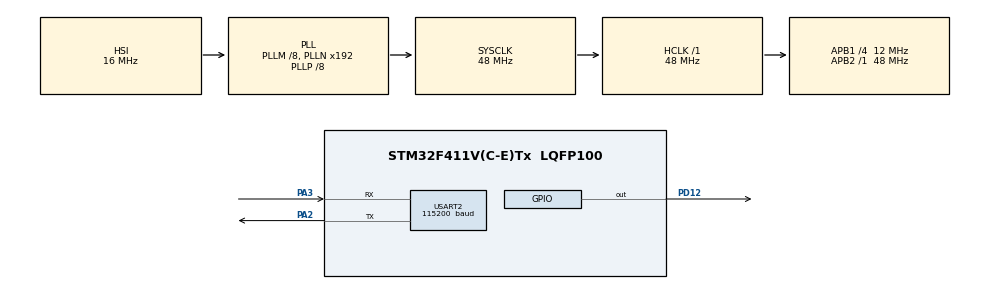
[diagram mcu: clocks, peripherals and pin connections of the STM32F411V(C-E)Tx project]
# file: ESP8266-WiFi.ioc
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Mcu.Family=STM32F4
Mcu.Name=STM32F411V(C-E)Tx
Mcu.Package=LQFP100
NVIC.PriorityGroup=NVIC_PRIORITYGROUP_0
NVIC.USART2_IRQn=true\:0\:0\:false\:false\:true\:true\:true\:true
PA2.Mode=Asynchronous
PA2.Signal=USART2_TX
PA3.Mode=Asynchronous
PA3.Signal=USART2_RX
PD12.Signal=GPIO_Output
ProjectManager.HeapSize=0x200
ProjectManager.StackSize=0x400
ProjectManager.TargetToolchain=STM32CubeIDE
RCC.48MHZClocksFreq_Value=48000000
RCC.AHBFreq_Value=48000000
RCC.APB1CLKDivider=RCC_HCLK_DIV4
RCC.APB1Freq_Value=12000000
RCC.APB1TimFreq_Value=24000000
RCC.APB2Freq_Value=48000000
RCC.APB2TimFreq_Value=48000000
RCC.CortexFreq_Value=48000000
RCC.HCLKFreq_Value=48000000
RCC.HSE_VALUE=8000000
RCC.HSI_VALUE=16000000
RCC.LSE_VALUE=32768
RCC.PLLI2SM=5
RCC.PLLI2SN=200
RCC.PLLM=8
RCC.PLLP=RCC_PLLP_DIV8
RCC.PLLQ=8
RCC.SYSCLKFreq_VALUE=48000000
RCC.SYSCLKSource=RCC_SYSCLKSOURCE_PLLCLK
RCC.VCOOutputFreq_Value=384000000
USART2.BaudRate=115200 
USART2.VirtualMode=VM_ASYNC
board=STM32F411E-DISCO

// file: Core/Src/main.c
/* USER CODE BEGIN Header */
/**
  ******************************************************************************
  * @file           : main.c
  * @brief          : Main program body
  ******************************************************************************
  * @attention
  *
  * Copyright (c) 2025 STMicroelectronics.
  * All rights reserved.
  *
  * This software is licensed under terms that can be found in the LICENSE file
  * in the root directory of this software component.
  * If no LICENSE file comes with this software, it is provided AS-IS.
  *
  ******************************************************************************
  */
/* USER CODE END Header */
#include "main.h"

/* USER CODE BEGIN Includes */
#include <string.h>
#include <stdio.h>
#include <stdlib.h>
#include <stdbool.h>  // Necesario para usar bool en C

/* USER CODE END Includes */

/* USER CODE BEGIN PD */
#define WIFI_SSID "MOVISTAR_1DD2"
#define WIFI_PASS "55253A2D16DDBF32D47B"
#define THINGSPEAK_API_KEY "6K0OKMK195CFJ8SQ"
/* USER CODE END PD */

UART_HandleTypeDef huart2;

/* USER CODE BEGIN PV */
char response[256];  // Buffer para almacenar la respuesta (aumentado a 256 bytes)
volatile uint8_t rxIndex = 0; // Índice de recepción
volatile uint8_t rxComplete = 0; // Bandera de recepción completa
uint8_t flagConexion = 0; // Bandera de recepción completa

/* USER CODE END PV */

void SystemClock_Config(void);
static void MX_GPIO_Init(void);
static void MX_USART2_UART_Init(void);
static void MX_NVIC_Init(void); // Agregar prototipo para NVIC init
/* USER CODE BEGIN PFP */

void sendATCommand(char *cmd) {
    HAL_UART_Transmit(&huart2, (uint8_t*)cmd, strlen(cmd), HAL_MAX_DELAY);
}

void receiveResponse_IT() {
    rxIndex = 0;  // Reiniciar índice
    rxComplete = 0;  // Limpiar bandera de recepción completa
    memset(response, 0, sizeof(response));  // Limpiar el buffer
    HAL_UART_Receive_IT(&huart2, (uint8_t*)&response[rxIndex], 1);  // Recibir primer byte
}

void HAL_UART_RxCpltCallback(UART_HandleTypeDef *huart) {
    if (huart->Instance == USART2) {  // Verificar si es el UART correcto
        if (rxIndex < sizeof(response) - 1) {  // Evitar desbordamiento del buffer
            rxIndex++;  // Avanzar índice
            if (response[rxIndex - 1] == '\n') {  // Detecta el fin de la respuesta
                rxComplete = 1;  // Marcar recepción completa
            } else {
                HAL_UART_Receive_IT(&huart2, (uint8_t*)&response[rxIndex], 1);  // Recibir siguiente byte
            }
        } else {
            rxComplete = 1;  // Si se llena el buffer, finalizar recepción
        }
    }
}

void connectToWiFi() {
    HAL_Delay(3000);  // Esperar 3s después de encender el ESP8266

    // Enviar comando AT y esperar respuesta con interrupciones
    sendATCommand("AT\r\n");
    receiveResponse_IT();
    while (!rxComplete);
    printf("Respuesta AT: %s\n", response);
    rxComplete = 0;

    // Reiniciar el ESP8266
    sendATCommand("AT+RST\r\n");
    receiveResponse_IT();
    HAL_Delay(5000);
    while (!rxComplete);
    printf("Respuesta RST: %s\n", response);
    rxComplete = 0;

    // Configurar modo Station
    sendATCommand("AT+CWMODE=1\r\n");
    receiveResponse_IT();
    HAL_Delay(1000);
    while (!rxComplete);
    printf("Respuesta CWMODE: %s\n", response);
    rxComplete = 0;

    // Conectar a WiFi
    char connectCmd[100];
    sprintf(connectCmd, "AT+CWJAP=\"%s\",\"%s\"\r\n", WIFI_SSID, WIFI_PASS);
    sendATCommand(connectCmd);
    receiveResponse_IT();
    HAL_Delay(15000);
    while (!rxComplete);
    printf("Respuesta CWJAP: %s\n", response);
    rxComplete = 0;

    // Verificar si la conexión fue exitosa
    if (strstr(response, "WIFI CONNECTED") != NULL) {
        HAL_GPIO_WritePin(GPIOD, GPIO_PIN_12, GPIO_PIN_SET);  // Encender LED
    } else {
        HAL_GPIO_WritePin(GPIOD, GPIO_PIN_12, GPIO_PIN_RESET);  // Apagar LED
    }
}

void sendDataToThingSpeak(float temperature) {
    char cmd[100];
    sprintf(cmd, "AT+CIPSTART=\"TCP\",\"api.thingspeak.com\",80\r\n");
    sendATCommand(cmd);
    HAL_Delay(2000);

    char http_request[150];
    sprintf(http_request, "GET /update?api_key=%s&field1=%.2f HTTP/1.1\r\nHost: api.thingspeak.com\r\nConnection: close\r\n\r\n", THINGSPEAK_API_KEY, temperature);

    char http_cmd[50];
    sprintf(http_cmd, "AT+CIPSEND=%d\r\n", strlen(http_request));
    sendATCommand(http_cmd);
    HAL_Delay(1000);
    sendATCommand(http_request);
    HAL_Delay(2000);
}

/* USER CODE END PFP */

int main(void)
{
  /* USER CODE BEGIN 1 */
  float temperature = 22.5; // Valor de temperatura de ejemplo
  /* USER CODE END 1 */

  /* MCU Configuration--------------------------------------------------------*/

  /* Reset of all peripherals, Initializes the Flash interface and the Systick. */
  HAL_Init();

  /* Configure the system clock */
  SystemClock_Config();

  /* Initialize all configured peripherals */
  MX_GPIO_Init();
  MX_USART2_UART_Init();
  MX_NVIC_Init(); // Inicializar NVIC
  /* USER CODE BEGIN 2 */
  flagConexion = 0;
  HAL_Delay(3000);  // Esperar 3s después de encender el ESP8266

  connectToWiFi();
  flagConexion = 1;

  bzero(response, sizeof(response));

  HAL_Delay(5000);
  sendDataToThingSpeak(temperature);
  flagConexion = 6;

  /* USER CODE END 2 */

  /* Infinite loop */
  while (1)
  {

    /* USER CODE BEGIN 3 */
    HAL_Delay(5000);
  }
  /* USER CODE END 3 */
}

void SystemClock_Config(void)
{
  RCC_OscInitTypeDef RCC_OscInitStruct = {0};
  RCC_ClkInitTypeDef RCC_ClkInitStruct = {0};

  /** Configure the main internal regulator output voltage
  */
  __HAL_RCC_PWR_CLK_ENABLE();
  __HAL_PWR_VOLTAGESCALING_CONFIG(PWR_REGULATOR_VOLTAGE_SCALE1);

  /** Initializes the RCC Oscillators according to the specified parameters
  * in the RCC_OscInitTypeDef structure.
  */
  RCC_OscInitStruct.OscillatorType = RCC_OSCILLATORTYPE_HSI;
  RCC_OscInitStruct.HSIState = RCC_HSI_ON;
  RCC_OscInitStruct.HSICalibrationValue = RCC_HSICALIBRATION_DEFAULT;
  RCC_OscInitStruct.PLL.PLLState = RCC_PLL_ON;
  RCC_OscInitStruct.PLL.PLLSource = RCC_PLLSOURCE_HSI;
  RCC_OscInitStruct.PLL.PLLM = 8;
  RCC_OscInitStruct.PLL.PLLN = 192;
  RCC_OscInitStruct.PLL.PLLP = RCC_PLLP_DIV8;
  RCC_OscInitStruct.PLL.PLLQ = 8;
  if (HAL_RCC_OscConfig(&RCC_OscInitStruct) != HAL_OK)
  {
    Error_Handler();
  }

  /** Initializes the CPU, AHB and APB buses clocks
  */
  RCC_ClkInitStruct.ClockType = RCC_CLOCKTYPE_HCLK|RCC_CLOCKTYPE_SYSCLK
                              |RCC_CLOCKTYPE_PCLK1|RCC_CLOCKTYPE_PCLK2;
  RCC_ClkInitStruct.SYSCLKSource = RCC_SYSCLKSOURCE_PLLCLK;
  RCC_ClkInitStruct.AHBCLKDivider = RCC_SYSCLK_DIV1;
  RCC_ClkInitStruct.APB1CLKDivider = RCC_HCLK_DIV4;
  RCC_ClkInitStruct.APB2CLKDivider = RCC_HCLK_DIV1;

  if (HAL_RCC_ClockConfig(&RCC_ClkInitStruct, FLASH_LATENCY_1) != HAL_OK)
  {
    Error_Handler();
  }
}

static void MX_USART2_UART_Init(void)
{

  huart2.Instance = USART2;
  huart2.Init.BaudRate = 115200 ;
  huart2.Init.WordLength = UART_WORDLENGTH_8B;
  huart2.Init.StopBits = UART_STOPBITS_1;
  huart2.Init.Parity = UART_PARITY_NONE;
  huart2.Init.Mode = UART_MODE_TX_RX;
  huart2.Init.HwFlowCtl = UART_HWCONTROL_NONE;
  huart2.Init.OverSampling = UART_OVERSAMPLING_16;
  if (HAL_UART_Init(&huart2) != HAL_OK)
  {
    Error_Handler();
  }

}

static void MX_NVIC_Init(void)
{
  /* USART2_IRQn interrupt configuration */
  HAL_NVIC_SetPriority(USART2_IRQn, 0, 0);
  HAL_NVIC_EnableIRQ(USART2_IRQn); // Habilitar interrupciones globales USART2
}

static void MX_GPIO_Init(void)
{
  GPIO_InitTypeDef GPIO_InitStruct = {0};

  /* GPIO Ports Clock Enable */
  __HAL_RCC_GPIOA_CLK_ENABLE();
  __HAL_RCC_GPIOD_CLK_ENABLE();

  /*Configure GPIO pin Output Level */
  HAL_GPIO_WritePin(GPIOD, GPIO_PIN_12, GPIO_PIN_RESET);

  /*Configure GPIO pin : PD12 */
  GPIO_InitStruct.Pin = GPIO_PIN_12;
  GPIO_InitStruct.Mode = GPIO_MODE_OUTPUT_PP;
  GPIO_InitStruct.Pull = GPIO_NOPULL;
  GPIO_InitStruct.Speed = GPIO_SPEED_FREQ_LOW;
  HAL_GPIO_Init(GPIOD, &GPIO_InitStruct);

}

void Error_Handler(void)
{
  __disable_irq();
  while (1)
  {
  }
}

#ifdef __GNUC__
    #define PUTCHAR_PROTOTYPE int __io_putchar(int ch)
#else
    #define PUTCHAR_PROTOTYPE int fputc(int ch, FILE *f)
#endif /* __GNUC__ */
